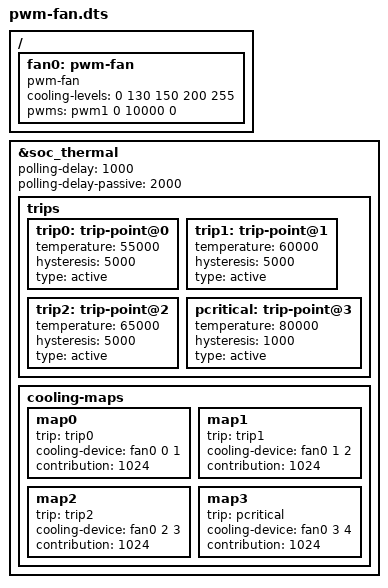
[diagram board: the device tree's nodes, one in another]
/dts-v1/;
/plugin/;
/ {
        fragment@0 {
                target-path = "/";
                __overlay__ {
			fan0: pwm-fan {
				compatible = "pwm-fan";
				#cooling-cells = <2>;
				cooling-levels = <0 130 150 200 255>;
				pwms = <&pwm1 0 10000 0>;
			};
		};
	};
        fragment@1 {
                target = <&soc_thermal>;
                __overlay__ {
			polling-delay = <1000>;
			polling-delay-passive = <2000>;
			trips {
				trip0: trip-point@0 {
					temperature = <55000>;
					hysteresis = <5000>;
					type = "active";
				};
				trip1: trip-point@1 {
					temperature = <60000>;
					hysteresis = <5000>;
					type = "active";
				};
				trip2: trip-point@2 {
					temperature = <65000>;
					hysteresis = <5000>;
					type = "active";
				};
				pcritical: trip-point@3 {
					temperature = <80000>;
					hysteresis = <1000>;
					type = "active";
				};
			};
			cooling-maps {
				map0 {
					trip = <&trip0>;
					cooling-device = <&fan0 0 1>;
					contribution = <1024>;
				};
				map1 {
					trip = <&trip1>;
					cooling-device = <&fan0 1 2>;
					contribution = <1024>;
				};
				map2 {
					trip = <&trip2>;
					cooling-device = <&fan0 2 3>;
					contribution = <1024>;
				};
				map3 {
					trip = <&pcritical>;
					cooling-device = <&fan0 3 4>;
					contribution = <1024>;
				};

			};
		};
	};
};
